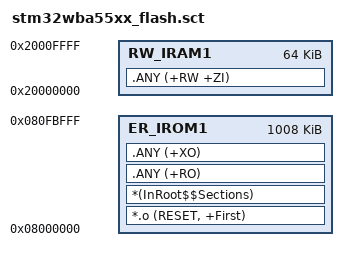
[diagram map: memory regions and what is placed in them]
; *************************************************************
; *** Scatter-Loading Description File                      ***
; *************************************************************

LR_IROM1 0x08000000 0x000FC000 {
  ER_IROM1 0x08000000 0x000FC000 {
    *.o (RESET, +First)
    *(InRoot$$Sections)
    .ANY (+RO)
    .ANY (+XO)
  }

  RW_IRAM1 0x20000000 0x00010000 {
    .ANY (+RW +ZI)
  }
}

; NVM zone on Flash, not linked : 0x080FC000 0x4000
